AUTOSAR XML (schema 4-0-3)
standard types defined: UInt16
package /AUTOSAR_Platform/DataConstrs
  range DC_UInt16: raw 0..65535
package /PATAC/MSM/ComponentTypes
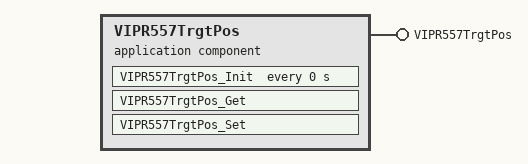
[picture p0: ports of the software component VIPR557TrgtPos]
  application sw component type VIPR557TrgtPos
    provide port VIPR557TrgtPos: provided-com-specs=[{operation=Get, queue-length=1}, {operation=Set, queue-length=1}], provided-interface=VIPR557TrgtPos
    behavior VIPR557TrgtPos_InternalBehavior
      operation invoked event OIT_VIPR557TrgtPos_Get_VIPR557TrgtPos_Get: start-on-event=VIPR557TrgtPos_Get, operation=VIPR557TrgtPos.Get
      timing event VIPR557TrgtPos_InitEvent: start-on-event=VIPR557TrgtPos_Init, period=0
      operation invoked event OIT_VIPR557TrgtPos_Set_VIPR557TrgtPos_Set: start-on-event=VIPR557TrgtPos_Set, operation=VIPR557TrgtPos.Set
      runnable VIPR557TrgtPos_Get
      runnable VIPR557TrgtPos_Init
      runnable VIPR557TrgtPos_Set
  swc implementation VIPR557TrgtPos_Implementation: behavior=VIPR557TrgtPos_InternalBehavior
    code-descriptors:
      code Default: artifact-descriptors=autosar-engineering-object={short-label=Default, category=SWSRC}
package /PATAC/MSM/ModeAdjust/PortInterface
  client server interface VIPR557TrgtPos
    operation Get
      5 x arg, all with type=UInt16, direction=OUT, server-argument-impl-policy=USE-ARGUMENT-TYPE:
        SecRwLtStBkReclnTrgtPos
        SecRwLtStZeroTrgtPos
        SecRwLtStLgrstUpwdDnwdTrgtPos
        SecRwLtStLgrstInwdOtwdTrgtPos
        SecRwLtStFwdBkwdTrgtPos
    operation Set
      5 x arg, all with type=UInt16, direction=IN, server-argument-impl-policy=USE-ARGUMENT-TYPE:
        SecRwLtStBkReclnTrgtPos
        SecRwLtStZeroTrgtPos
        SecRwLtStLgrstUpwdDnwdTrgtPos
        SecRwLtStLgrstInwdOtwdTrgtPos
        SecRwLtStFwdBkwdTrgtPos
